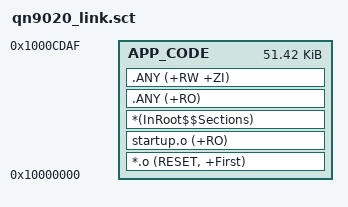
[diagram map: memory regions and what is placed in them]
; *************************************************************
; *** Scatter-Loading Description File generated by Quintic ***
; *************************************************************
LR_ROM1 0x10000000 0xCDB0
{
    APP_CODE 0x10000000 0xCDB0
    {
        *.o (RESET, +First)
        startup.o (+RO)
        *(InRoot$$Sections)
        .ANY (+RO)
        .ANY (+RW +ZI)
    }
}

